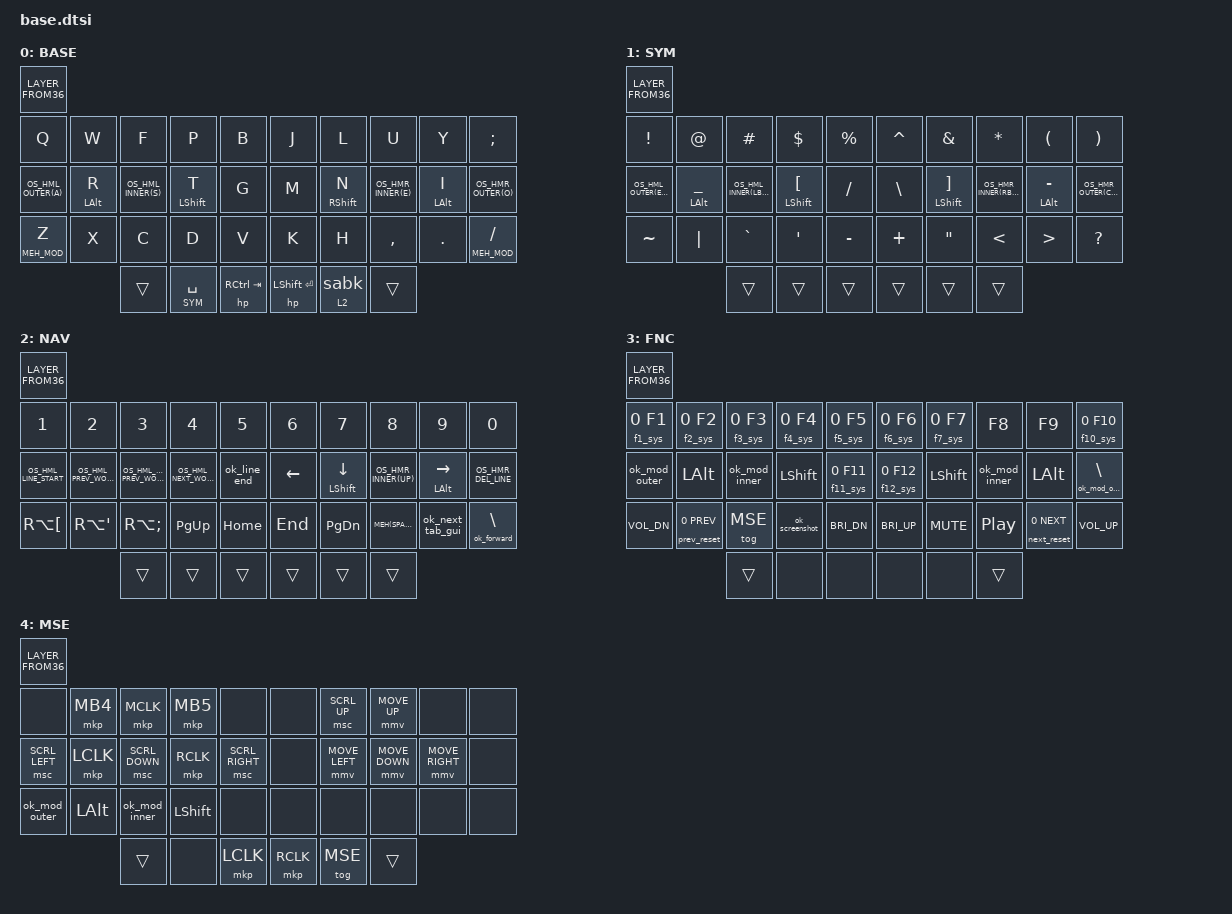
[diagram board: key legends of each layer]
#include <behaviors.dtsi>
#include <dt-bindings/zmk/keys.h>
#include <dt-bindings/zmk/bt.h>
#include <dt-bindings/zmk/oskey.h>
#include <dt-bindings/zmk/outputs.h>
#include <behaviors/rgbled_widget.dtsi> // rgb led indicator for battery and connection
#include <behaviors/case_mode.dtsi> // case_modes behaviors

// Layer definitions
#define BASE 0
#define SYM 1
#define NAV 2
#define FNC 3
#define MSE 4

#define MEH(k) LC(LA(LS(k)))
#define MEH_MOD LA(LS(LCTRL))

#include "mouse.dtsi"
#include "oskey.dtsi"
#include "hold-taps.dtsi"
#include "combos.dtsi"

&caps_word { continue-list = <UNDERSCORE BACKSPACE DELETE MINUS DEL N1 N2 N3 N4 N5 N6 N7 N8 N9 N0>; };

/ {
    macros {
        sys_bt_0: sys_bt_0 {
            compatible = "zmk,behavior-macro";
            #binding-cells = <0>;
            bindings = <&bt BT_SEL 0>;
        };

        bt_lin: bt_lin {
            compatible = "zmk,behavior-macro";
            #binding-cells = <0>;
            bindings = <&bt BT_SEL 1>, <&os_sel OS_LIN>;
        };

        sys_bt_2: sys_bt_2 {
            compatible = "zmk,behavior-macro";
            #binding-cells = <0>;
            bindings = <&bt BT_SEL 2>;
        };

        sys_bt_3: sys_bt_3 {
            compatible = "zmk,behavior-macro";
            #binding-cells = <0>;
            bindings = <&bt BT_SEL 3>;
        };

        sys_out_usb: sys_out_usb {
            compatible = "zmk,behavior-macro";
            #binding-cells = <0>;
            bindings = <&out OUT_USB>;
        };

        sys_out_ble: sys_out_ble {
            compatible = "zmk,behavior-macro";
            #binding-cells = <0>;
            bindings = <&out OUT_BLE>;
        };

        sys_bt_clear: sys_bt_clear {
            compatible = "zmk,behavior-macro";
            #binding-cells = <0>;
            bindings = <&bt BT_CLR>;
        };

        sys_soft_off: sys_soft_off {
            compatible = "zmk,behavior-macro";
            #binding-cells = <0>;
            // Finish without a physical key release after the peripherals turn off.
            tap-ms = <100>;
            bindings = <&soft_off>;
        };
        sabk: shift_to_alt_backspace {
            compatible = "zmk,behavior-mod-morph";
            #binding-cells = <0>;
            bindings = <&kp BSPC>, <&kp LA(BSPC)>;
            mods = <(MOD_LSFT|MOD_RSFT)>;
        };
        sym_bspc: left_thumb_hold_tap {
            compatible = "zmk,behavior-hold-tap";
            #binding-cells = <2>;
            flavor = "tap-preferred";
            tapping-term-ms = <150>;
            quick-tap-ms = <200>;
            bindings = <&mo>, <&sabk>;
        };
    };

   cond_layers {
        compatible = "zmk,conditional-layers";
        // Define FNC layer as tri-state
        func_tristate {
            if-layers = <SYM NAV>;
            then-layer = <FNC>;
        };
    };

    keymap {
        compatible = "zmk,keymap";

        base {
            display-name = "BASE";
            bindings = <LAYER_FROM36( \
// ╭─────────────┬─────────────┬─────────────┬─────────────┬─────────────╮   ╭───────────────┬───────────────┬───────────────┬─────────────┬───────────────╮
     &kp Q,        &kp W,        &kp F,        &kp P,        &kp B,            &kp J,          &kp L,          &kp U,          &kp Y,        &kp SEMI,      \
// ├─────────────┼─────────────┼─────────────┼─────────────┼─────────────┤   ├───────────────┼───────────────┼───────────────┼─────────────┼───────────────┤
     OS_HML_OUTER(A), &hml LALT R,  OS_HML_INNER(S), &hml LSHFT T, &kp G,      &kp M,          &hmr RSHFT N, OS_HMR_INNER(E),  &hmr LALT I,  OS_HMR_OUTER(O),\
// ├─────────────┼─────────────┼─────────────┼─────────────┼─────────────┤   ├───────────────┼───────────────┼───────────────┼─────────────┼───────────────┤
     &hml MEH_MOD Z, &kp X,      &kp C,        &kp D,       &kp V,             &kp K,          &kp H,          &kp COMMA,      &kp DOT,      &hmr MEH_MOD SLASH, \
// ╰─────────────┴─────────────┴─────────────┼─────────────┼─────────────┤   ├───────────────┼───────────────┼───────────────┴─────────────┴───────────────╯
                                 &trans,       &lth SYM SPACE, &hp RCTRL TAB,  &hp LSHFT ENTER, &sym_bspc 2 0, &trans
//                             ╰─────────────┴─────────────┴─────────────╯   ╰───────────────┴───────────────┴─────────────╯
            )>;
        };

        symbol {
          display-name = "SYM";
          bindings = <LAYER_FROM36( \
// ╭───────────────┬───────────────┬───────────────┬────────────────────┬───────────────╮   ╭───────────────┬────────────────────┬────────────────────┬────────────────────┬────────────────────╮
    &kp EXCL,        &kp AT_SIGN,     &kp HASH,        &kp DLLR,           &kp PRCNT,         &kp CARET,       &kp AMPS,            &kp ASTERISK,          &kp LPAR,             &kp RPAR,      \
// ├───────────────┼───────────────┼───────────────┼────────────────────┼───────────────┤   ├───────────────┼────────────────────┼────────────────────┼────────────────────┼────────────────────┤
    OS_HML_OUTER(EQUAL), &hml LALT UNDER, OS_HML_INNER(LBRC), &hml LSHFT LBKT,   &kp SLASH,          &kp BSLH,        &hmr LSHFT RBKT,    OS_HMR_INNER(RBRC),    &hmr LALT MINUS,     OS_HMR_OUTER(COLON), \
// ├───────────────┼───────────────┼───────────────┼────────────────────┼───────────────┤   ├───────────────┼────────────────────┼────────────────────┼────────────────────┼────────────────────┤
      &kp TILDE,       &kp PIPE,       &kp GRAVE,       &kp SQT,            &kp MINUS,         &kp PLUS,        &kp DOUBLE_QUOTES,  &kp LESS_THAN,       &kp GREATER_THAN,     &kp QUESTION,    \
// ╰───────────────┴───────────────┴───────────────┼────────────────────┼───────────────┤   ├───────────────┼────────────────────┴────────────────────┴────────────────────┴────────────────────╯
                                       &trans,          &trans,             &trans,              &trans,        &trans,             &trans       \
//                                 ╰───────────────┴────────────────────┴───────────────╯   ╰───────────────┴────────────────────┴───────────────╯
         )>;
      };

        nav_number {
            display-name = "NAV";
            bindings = <LAYER_FROM36( \
// ╭──────────────────┬───────────────┬────────────────────┬─────────────────┬──────────────╮   ╭────────────────────┬─────────────────┬───────────────┬──────────────────┬─────────────────────╮
     &kp N1,               &kp N2,      &kp N3,              &kp N4,           &kp N5,             &kp N6,             &kp N7,            &kp N8,        &kp N9,            &kp N0,             \
// ├──────────────────┼───────────────┼────────────────────┼─────────────────┼──────────────┤   ├────────────────────┼─────────────────┼───────────────┼──────────────────┼─────────────────────┤
    OS_HML_LINE_START, OS_HML_PREV_WORD, OS_HML_DEL_PREV_WORD, OS_HML_NEXT_WORD, &ok_line_end,     &kp LEFT,          &hmr LSHFT DOWN,  OS_HMR_INNER(UP), &hmr LALT RIGHT,  OS_HMR_DEL_LINE, \
// ├──────────────────┼───────────────┼────────────────────┼─────────────────┼──────────────┤   ├────────────────────┼─────────────────┼───────────────┼──────────────────┼─────────────────────┤
     &kp RA(LBKT),      &kp RA(APOS),   &kp RA(SEMI),        &kp PG_UP,        &kp HOME,           &kp END,           &kp PG_DN,         &kp MEH(SPACE), &ok_next_tab_gui, &ok_forward,       \
// ╰──────────────────┴───────────────┴────────────────────┼─────────────────┼──────────────┤   ├────────────────────┴─────────────────┴───────────────┴──────────────────┴─────────────────────╯
                                              &trans,        &trans,           &trans,             &trans,               &trans,              &trans   \
//                                    ╰────────────────────┴─────────────────┴──────────────╯   ╰────────────────────┴─────────────────┴───────────────╯
        )>;
      };

        settings_function {
            display-name = "FNC";
            bindings = <LAYER_FROM36( \
// ╭────────────────────┬────────────────────┬────────────────────┬────────────────────┬────────────────────╮   ╭─────────────────┬─────────────────┬───────────────┬───────────────┬────────────────────╮
     &f1_sys 0 F1,         &f2_sys 0 F2,         &f3_sys 0 F3,         &f4_sys 0 F4,       &f5_sys 0 F5,           &f6_sys 0 F6,     &f7_sys 0 F7,   &kp F8,          &kp F9,          &f10_sys 0 F10, \
// ├────────────────────┼────────────────────┼────────────────────┼────────────────────┼────────────────────┤   ├─────────────────┼─────────────────┼───────────────┼───────────────┼────────────────────┤
     &ok_mod_outer,        &kp LALT,             &ok_mod_inner,        &kp LSHFT,         &f11_sys 0 F11,           &f12_sys 0 F12,   &kp LSHFT,       &ok_mod_inner,   &kp LALT,        &ok_mod_outer,   \
// ├────────────────────┼────────────────────┼────────────────────┼────────────────────┼────────────────────┤   ├─────────────────┼─────────────────┼───────────────┼───────────────┼────────────────────┤
     &kp C_VOL_DN,        &prev_reset 0 C_PREV,            &tog MSE,            &ok_screenshot,    &kp C_BRI_DN,            &kp C_BRI_UP,      &kp C_MUTE,      &kp C_PP,        &next_reset 0 C_NEXT,      &kp C_VOL_UP,    \
// ╰────────────────────┴────────────────────┴────────────────────┼────────────────────┼────────────────────┤   ├─────────────────┴─────────────────┴───────────────┴───────────────┴────────────────────╯
                                                &trans,               &none,               &none,                  &none,            &none,           &trans         \
//                                           ╰────────────────────┴────────────────────┴────────────────────╯   ╰─────────────────┴─────────────────┴────────────────╯
         )>;
      };

        mouse_layer {
            display-name = "MSE";
            bindings = <LAYER_FROM36( \
// ╭────────────────────┬───────────────┬────────────────────┬───────────────┬────────────────────╮   ╭─────────────────┬────────────────────┬────────────────────┬────────────────────┬────────────────────╮
     &none,               &mkp MB4,         &mkp MCLK,          &mkp MB5,      &none,                   &none,                &msc SCRL_UP,       &mmv MOVE_UP,       &none,                 &none,         \
// ├────────────────────┼───────────────┼────────────────────┼───────────────┼────────────────────┤   ├─────────────────┼────────────────────┼────────────────────┼────────────────────┼────────────────────┤
     &msc SCRL_LEFT,      &mkp LCLK,        &msc SCRL_DOWN,     &mkp RCLK,     &msc SCRL_RIGHT,         &none,                &mmv MOVE_LEFT,     &mmv MOVE_DOWN,    &mmv MOVE_RIGHT,        &none,         \
// ├────────────────────┼───────────────┼────────────────────┼───────────────┼────────────────────┤   ├─────────────────┼────────────────────┼────────────────────┼────────────────────┼────────────────────┤
     &ok_mod_outer,       &kp LALT,         &ok_mod_inner,      &kp LSHFT,      &none,                    &none,                &none,                 &none,         &none,                  &none,         \
// ╰────────────────────┴───────────────┴────────────────────┼───────────────┼────────────────────┤   ├─────────────────┴────────────────────┴────────────────────┴────────────────────┴────────────────────╯
                                                &trans,         &none,         &mkp LCLK,               &mkp RCLK,            &tog MSE,              &trans       \
//                                      ╰────────────────────┴───────────────┴────────────────────╯   ╰─────────────────┴────────────────────┴────────────────────╯
         )>;
        };
    };

};
